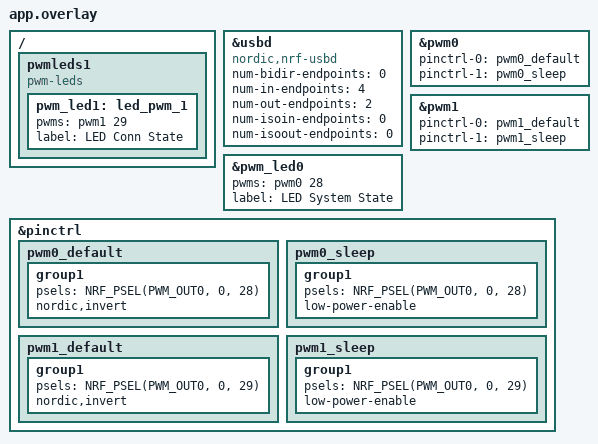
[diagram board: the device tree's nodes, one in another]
/ {
	pwmleds1 {
		compatible = "pwm-leds";
		status = "okay";

		pwm_led1: led_pwm_1 {
			status = "okay";
			pwms = <&pwm1 29>;
			label = "LED Conn State";
		};
	};
};

&usbd {
	compatible = "nordic,nrf-usbd";
	status = "okay";
	num-bidir-endpoints = <0>;
	num-in-endpoints = <4>;
	num-out-endpoints = <2>;
	num-isoin-endpoints = <0>;
	num-isoout-endpoints = <0>;
};

&pwm0 {
	status = "okay";
	pinctrl-0 = <&pwm0_default>;
	pinctrl-1 = <&pwm0_sleep>;
	pinctrl-names = "default", "sleep";
};

&pwm1 {
	status = "okay";
	pinctrl-0 = <&pwm1_default>;
	pinctrl-1 = <&pwm1_sleep>;
	pinctrl-names = "default", "sleep";
};

&pwm_led0 {
	status = "okay";
	pwms = <&pwm0 28>;
	label = "LED System State";
};

&pinctrl {
	pwm0_default: pwm0_default {
		group1 {
			psels = <NRF_PSEL(PWM_OUT0, 0, 28)>;
			nordic,invert;
		};
	};

	pwm0_sleep: pwm0_sleep {
		group1 {
			psels = <NRF_PSEL(PWM_OUT0, 0, 28)>;
			low-power-enable;
		};
	};

	pwm1_default: pwm1_default {
		group1 {
			psels = <NRF_PSEL(PWM_OUT0, 0, 29)>;
			nordic,invert;
		};
	};

	pwm1_sleep: pwm1_sleep {
		group1 {
			psels = <NRF_PSEL(PWM_OUT0, 0, 29)>;
			low-power-enable;
		};
	};

};
